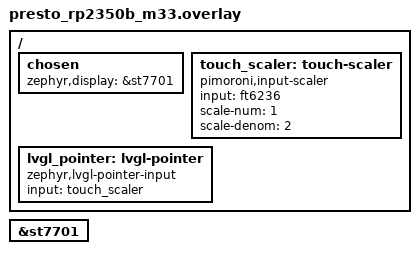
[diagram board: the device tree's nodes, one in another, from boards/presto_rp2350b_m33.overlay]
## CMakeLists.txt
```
cmake_minimum_required(VERSION 3.20.0)
list(APPEND BOARD_ROOT ${CMAKE_CURRENT_SOURCE_DIR}/../..)
list(APPEND ZEPHYR_EXTRA_MODULES ${CMAKE_CURRENT_SOURCE_DIR}/../../drivers/presto)
find_package(Zephyr REQUIRED HINTS $ENV{ZEPHYR_BASE})
project(test_lvgl)

target_sources(app PRIVATE src/main.c)
```

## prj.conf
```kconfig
# LVGL widget proof-of-concept: label + button + slider driven by touch.
#
# Portable config shared by the Presto and native_sim builds; the per-board
# files under boards/ add the display/touch/memory specifics.

CONFIG_DISPLAY=y
CONFIG_INPUT=y
CONFIG_LOG=y
CONFIG_LOG_DEFAULT_LEVEL=3
CONFIG_MAIN_STACK_SIZE=4096

CONFIG_LVGL=y
CONFIG_LV_COLOR_DEPTH_16=y
CONFIG_LV_USE_LABEL=y
CONFIG_LV_USE_BUTTON=y
CONFIG_LV_USE_SLIDER=y
CONFIG_LV_USE_THEME_DEFAULT=y
CONFIG_LV_FONT_MONTSERRAT_14=y

# Disable the default theme's "grow + fade" press animation. It scales a
# pressed widget up over 80 ms (the button/slider "bounce"), which also forces
# a stream of per-frame redraws during a press - undesirable on this
# continuously-scanned panel. Widgets still show their pressed colour state.
CONFIG_LV_THEME_DEFAULT_GROW=n
CONFIG_LV_THEME_DEFAULT_TRANSITION_TIME=0

# Default LVGL object heap (native_sim); the Presto build overrides the size
# and places it in PSRAM instead.
CONFIG_LV_Z_MEM_POOL_SIZE=65536
```

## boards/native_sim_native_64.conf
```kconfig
# Run the LVGL test on the host via Zephyr's SDL display emulator. Mouse
# clicks arrive through the input_sdl_touch node, so the widgets are fully
# interactive in the SDL window.

CONFIG_SDL_DISPLAY=y
```

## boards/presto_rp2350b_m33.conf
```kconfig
# Hardware-only options for the Presto board.

# Half-resolution 240x240 framebuffer (115 KB SRAM), pixel-doubled to the panel.
# Single-buffered: LVGL's partial rendering writes only the small dirty regions
# straight into the live framebuffer. On this continuous-scanout DPI panel that
# is the clean path - the per-frame CPU/bus work stays tiny, so it never
# disturbs the timing-critical PIO/DMA scanout. (Double-buffering with a vblank
# flip was tried and glitched: rebuilding the back buffer every frame - by copy
# or full redraw - plus a per-frame flip congests the scanout pipeline.)
CONFIG_ST7701_PRESTO_HALF_RES=y

# 8 MB PSRAM, exposed as the "PSRAM" linker region. LVGL object heap + render
# buffer live here (dynamic alloc sizes the buffer from the real 240x240
# resolution), leaving SRAM for the framebuffer.
CONFIG_PIMORONI_RP2350_PSRAM=y
CONFIG_LV_Z_MEMORY_POOL_ZEPHYR_REGION=y
CONFIG_LV_Z_MEMORY_POOL_ZEPHYR_REGION_NAME="PSRAM"
CONFIG_LV_Z_MEM_POOL_SIZE=262144
CONFIG_LV_Z_BUFFER_ALLOC_DYNAMIC=y
```

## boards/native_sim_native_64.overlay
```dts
/*
 * Match the Presto's half-res 240x240 geometry and feed SDL mouse/touch
 * events into LVGL. SDL reports display-space coordinates already, so no
 * scaling wrapper is needed here.
 */

/ {
	lvgl_pointer: lvgl-pointer {
		compatible = "zephyr,lvgl-pointer-input";
		input = <&input_sdl_touch>;
	};
};

&sdl_dc {
	width = <240>;
	height = <240>;
};
```

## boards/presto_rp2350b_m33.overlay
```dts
/*
 * Enable the ST7701 panel as the system display (see apps/test_display for
 * the GP1/UART0-RX sharing note) and route FT6236 touch events into LVGL.
 *
 * The FT6236 reports panel-space coordinates (~0-480) while the half-res LVGL
 * display is 240x240. The touch_scaler halves them on the input side, before
 * the LVGL pointer glue - which clamps coordinates to the display bounds, so
 * scaling any later (e.g. in an LVGL read callback) would be too late and
 * collapse the lower-right of the panel onto the centre.
 */

/ {
	chosen {
		zephyr,display = &st7701;
	};

	touch_scaler: touch-scaler {
		compatible = "pimoroni,input-scaler";
		input = <&ft6236>;
		scale-num = <1>;
		scale-denom = <2>;
	};

	lvgl_pointer: lvgl-pointer {
		compatible = "zephyr,lvgl-pointer-input";
		input = <&touch_scaler>;
	};
};

&st7701 {
	status = "okay";
};
```

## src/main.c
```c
/*
 * Copyright (c) 2026 Jonathan Beri
 * SPDX-License-Identifier: MIT
 *
 * LVGL proof-of-concept: a themed label + button + slider, driven by touch.
 * On the Presto the LVGL object heap lives in PSRAM (see the board .conf) and
 * the FT6236's panel-space touch coordinates are halved onto the 240x240
 * half-res display by the pimoroni,input-scaler node (see the board overlay).
 */

#include <zephyr/device.h>
#include <zephyr/devicetree.h>
#include <zephyr/drivers/display.h>
#include <zephyr/kernel.h>
#include <zephyr/logging/log.h>
#include <lvgl.h>

LOG_MODULE_REGISTER(test_lvgl, LOG_LEVEL_INF);

static uint32_t count;
static lv_obj_t *count_label;

static void btn_event_cb(lv_event_t *e)
{
	ARG_UNUSED(e);
	count++;
	lv_label_set_text_fmt(count_label, "Count: %u", count);
}

int main(void)
{
	const struct device *display = DEVICE_DT_GET(DT_CHOSEN(zephyr_display));

	if (!device_is_ready(display)) {
		LOG_ERR("display not ready");
		return 0;
	}

	/*
	 * Fixed layout: stop the screen from scrolling. Otherwise a press-drag
	 * (e.g. on the slider) is also taken as a scroll gesture and the whole
	 * screen elastically scrolls and bounces back.
	 */
	lv_obj_t *scr = lv_screen_active();

	lv_obj_remove_flag(scr, LV_OBJ_FLAG_SCROLLABLE);
	lv_obj_set_scrollbar_mode(scr, LV_SCROLLBAR_MODE_OFF);

	lv_obj_t *title = lv_label_create(scr);

	lv_label_set_text(title, "Presto LVGL PoC");
	lv_obj_align(title, LV_ALIGN_TOP_MID, 0, 8);

	lv_obj_t *btn = lv_button_create(scr);

	lv_obj_align(btn, LV_ALIGN_CENTER, 0, -20);
	lv_obj_add_event_cb(btn, btn_event_cb, LV_EVENT_CLICKED, NULL);

	lv_obj_t *btn_label = lv_label_create(btn);

	lv_label_set_text(btn_label, "Tap me");

	count_label = lv_label_create(scr);
	lv_label_set_text(count_label, "Count: 0");
	lv_obj_align(count_label, LV_ALIGN_CENTER, 0, 30);

	lv_obj_t *slider = lv_slider_create(scr);

	lv_obj_set_width(slider, lv_pct(70));
	lv_obj_align(slider, LV_ALIGN_BOTTOM_MID, 0, -24);

	lv_timer_handler();
	display_blanking_off(display);

	LOG_INF("LVGL UI up (%ux%u)", lv_display_get_horizontal_resolution(NULL),
		lv_display_get_vertical_resolution(NULL));

	while (1) {
		uint32_t sleep_ms = lv_timer_handler();

		k_msleep(MIN(sleep_ms, 100));
	}
	return 0;
}
```
